# STM32F070F6P6 register map
File version: 1.0
Registers are 32-bit, access not given, reset 0x0 unless marked. A register's access mark holds for its fields unless they carry their own. Offsets are from the block's base; [hi:lo] are bit positions; {n}, {i} and the like mark numbered series.

## USART2
Base 0x40004400
Same registers: USART1 0x40013800
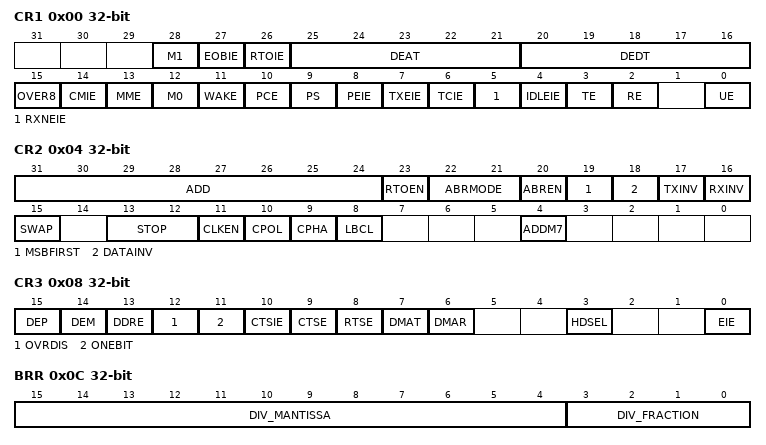
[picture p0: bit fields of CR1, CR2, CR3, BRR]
0x00 CR1
  [28] M1, [27] EOBIE, [26] RTOIE, [25:21] DEAT, [20:16] DEDT, [15] OVER8, [14] CMIE, [13] MME, [12] M0, [11] WAKE, [10] PCE, [9] PS, [8] PEIE, [7] TXEIE, [6] TCIE, [5] RXNEIE, [4] IDLEIE, [3] TE, [2] RE, [0] UE
0x04 CR2
  [31:24] ADD, [23] RTOEN, [22:21] ABRMODE, [20] ABREN, [19] MSBFIRST, [18] DATAINV, [17] TXINV, [16] RXINV, [15] SWAP, [13:12] STOP, [11] CLKEN, [10] CPOL, [9] CPHA, [8] LBCL, [4] ADDM7
0x08 CR3
  [15] DEP, [14] DEM, [13] DDRE, [12] OVRDIS, [11] ONEBIT, [10] CTSIE, [9] CTSE, [8] RTSE, [7] DMAT, [6] DMAR, [3] HDSEL, [0] EIE
0x0C BRR
  [15:4] DIV_MANTISSA, [3:0] DIV_FRACTION
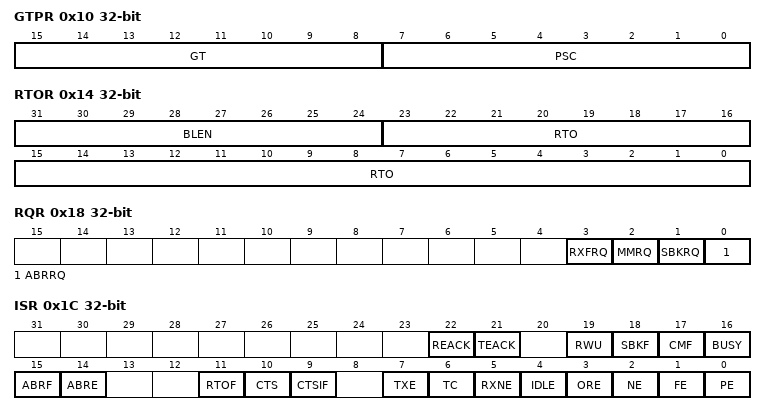
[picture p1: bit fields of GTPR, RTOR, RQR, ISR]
0x10 GTPR
  [15:8] GT, [7:0] PSC
0x14 RTOR
  [31:24] BLEN, [23:0] RTO
0x18 RQR
  [3] RXFRQ, [2] MMRQ, [1] SBKRQ, [0] ABRRQ
0x1C ISR
  [22] REACK, [21] TEACK, [19] RWU, [18] SBKF, [17] CMF, [16] BUSY, [15] ABRF, [14] ABRE, [11] RTOF, [10] CTS, [9] CTSIF, [7] TXE, [6] TC, [5] RXNE, [4] IDLE, [3] ORE, [2] NE, [1] FE, [0] PE
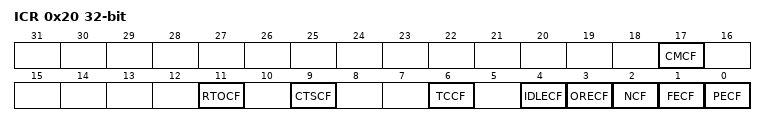
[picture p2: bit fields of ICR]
0x20 ICR
  [17] CMCF, [11] RTOCF, [9] CTSCF, [6] TCCF, [4] IDLECF, [3] ORECF, [2] NCF, [1] FECF, [0] PECF
0x24 RDR 16-bit
0x28 TDR 16-bit

## I2C1
Base 0x40005400
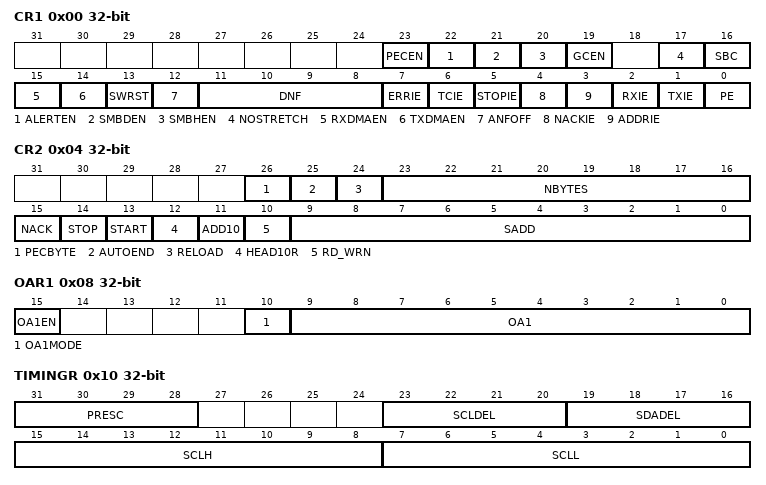
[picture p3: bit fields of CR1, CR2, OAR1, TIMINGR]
0x00 CR1
  [23] PECEN, [22] ALERTEN, [21] SMBDEN, [20] SMBHEN, [19] GCEN, [17] NOSTRETCH, [16] SBC, [15] RXDMAEN, [14] TXDMAEN, [13] SWRST, [12] ANFOFF, [11:8] DNF, [7] ERRIE, [6] TCIE, [5] STOPIE, [4] NACKIE, [3] ADDRIE, [2] RXIE, [1] TXIE, [0] PE
0x04 CR2
  [26] PECBYTE, [25] AUTOEND, [24] RELOAD, [23:16] NBYTES, [15] NACK, [14] STOP, [13] START, [12] HEAD10R, [11] ADD10, [10] RD_WRN, [9:0] SADD
0x08 OAR1
  [15] OA1EN, [10] OA1MODE, [9:0] OA1
0x0C OAR2
  [15] OA2EN, [10] OA2MASK04, [10:9] OA2MASK06, [10:8] OA2MSK, [7:1] OA2
0x10 TIMINGR
  [31:28] PRESC, [23:20] SCLDEL, [19:16] SDADEL, [15:8] SCLH, [7:0] SCLL
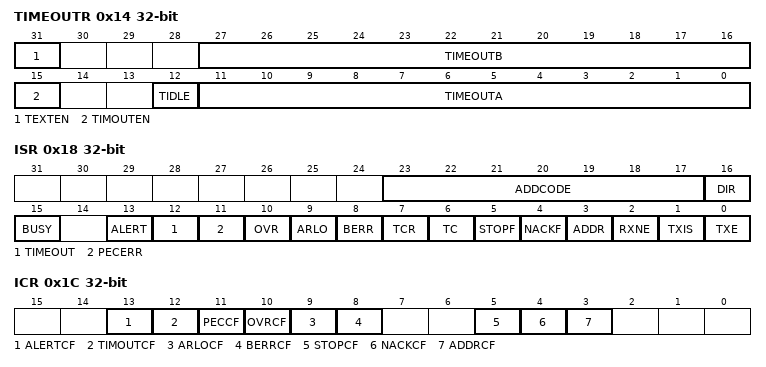
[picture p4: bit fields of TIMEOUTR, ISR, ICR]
0x14 TIMEOUTR
  [31] TEXTEN, [27:16] TIMEOUTB, [15] TIMOUTEN, [12] TIDLE, [11:0] TIMEOUTA
0x18 ISR
  [23:17] ADDCODE, [16] DIR, [15] BUSY, [13] ALERT, [12] TIMEOUT, [11] PECERR, [10] OVR, [9] ARLO, [8] BERR, [7] TCR, [6] TC, [5] STOPF, [4] NACKF, [3] ADDR, [2] RXNE, [1] TXIS, [0] TXE
0x1C ICR
  [13] ALERTCF, [12] TIMOUTCF, [11] PECCF, [10] OVRCF, [9] ARLOCF, [8] BERRCF, [5] STOPCF, [4] NACKCF, [3] ADDRCF
0x20 PECR
  [7:0] PEC
0x24 RXDR
  [7:0] RXDATA
0x28 TXDR
  [7:0] TXDATA

## USB
Base 0x40005C00
{0x0+4i} EP{i}R 16-bit (i=0..7)
0x40 CNTR 16-bit
0x44 ISTR 16-bit
0x48 FNR 16-bit
0x4C DADDR 16-bit
0x50 BTABLE 16-bit
0x54 LPMCSR 16-bit
0x58 BCDR 16-bit

## PWR
Base 0x40007000
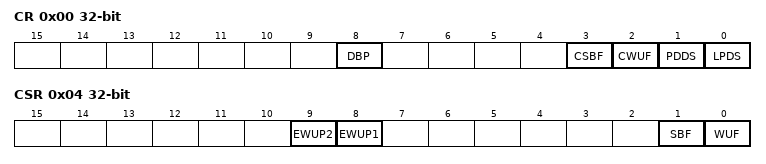
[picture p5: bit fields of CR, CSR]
0x00 CR
  [8] DBP, [3] CSBF, [2] CWUF, [1] PDDS, [0] LPDS
0x04 CSR
  [9] EWUP2, [8] EWUP1, [1] SBF, [0] WUF

## SYSCFG
Base 0x40010000
0x00 CFGR1
  [23] I2C_FMP_PA10, [22] I2C_FMP_PA9, [20] I2C_FMP_I2C1, [n+10] I2C_FMP_PB{n} (n=6..9), [12] TIM17_DMA_RMP, [11] TIM16_DMA_RMP, [10] USART1RX_DMA_RMP, [9] USART1TX_DMA_RMP, [12:8] DMA_RMP, [4] PA11_PA12_RMP, [1:0] MEM_MODE
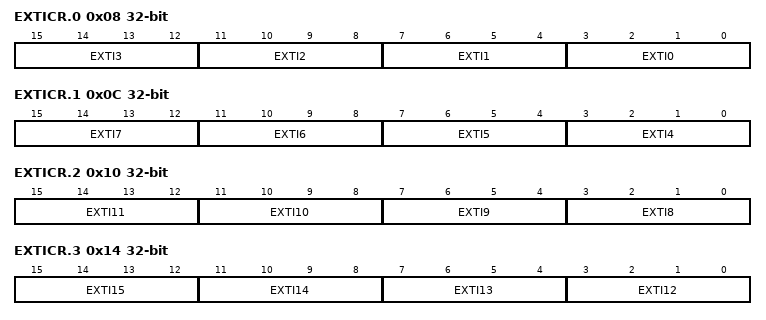
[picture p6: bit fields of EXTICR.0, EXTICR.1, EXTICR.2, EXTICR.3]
0x08 EXTICR.0
  [4n+3:4n] EXTI{n} (n=0..3)
0x0C EXTICR.1
  [4n-13:4n-16] EXTI{n} (n=4..7)
0x10 EXTICR.2
  [4n-29:4n-32] EXTI{n} (n=8..11)
0x14 EXTICR.3
  [4n-45:4n-48] EXTI{n} (n=12..15)
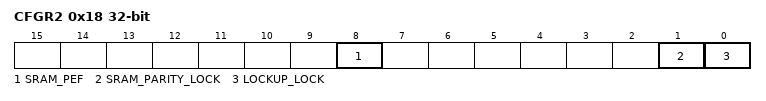
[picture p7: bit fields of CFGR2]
0x18 CFGR2
  [8] SRAM_PEF, [1] SRAM_PARITY_LOCK, [0] LOCKUP_LOCK

## EXTI
Base 0x40010400
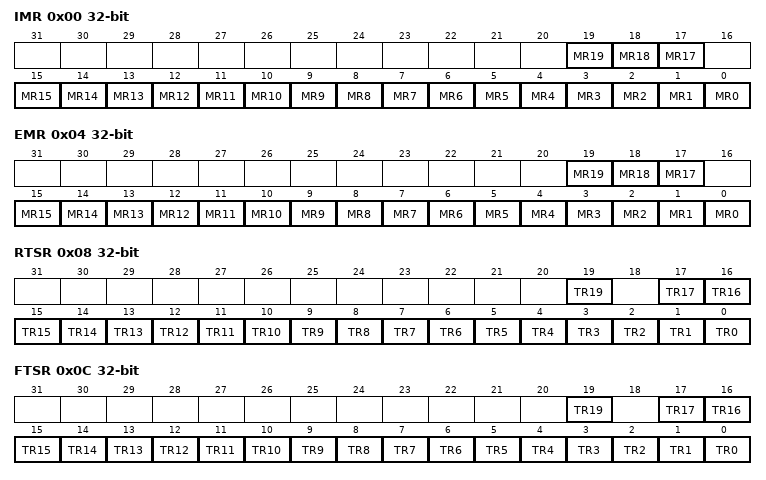
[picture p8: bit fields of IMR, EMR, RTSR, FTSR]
0x00 IMR
  [19] MR19, [18] MR18, [17] MR17, [n] MR{n} (n=0..15)
0x04 EMR
  [19] MR19, [18] MR18, [17] MR17, [n] MR{n} (n=0..15)
0x08 RTSR
  [19] TR19, [n] TR{n} (n=0..17)
0x0C FTSR
  [19] TR19, [n] TR{n} (n=0..17)
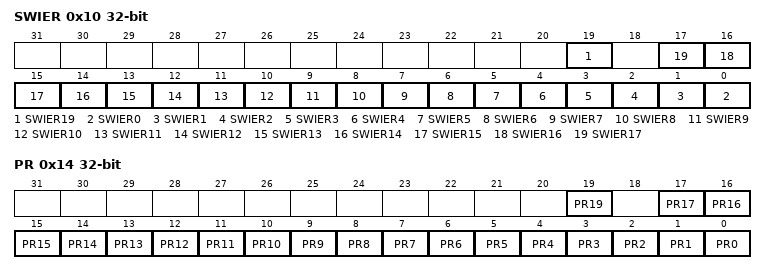
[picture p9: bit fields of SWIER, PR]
0x10 SWIER
  [19] SWIER19, [n] SWIER{n} (n=0..17)
0x14 PR
  [19] PR19, [n] PR{n} (n=0..17)

## ADC1
Base 0x40012400
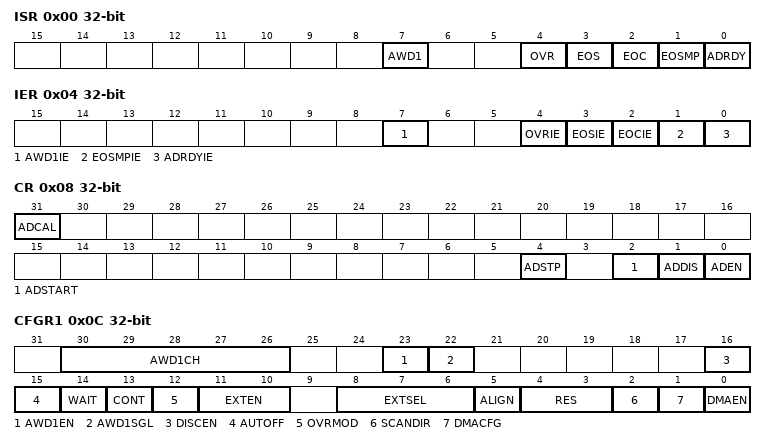
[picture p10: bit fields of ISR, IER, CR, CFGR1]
0x00 ISR
  [7] AWD1, [4] OVR, [3] EOS, [2] EOC, [1] EOSMP, [0] ADRDY
0x04 IER
  [7] AWD1IE, [4] OVRIE, [3] EOSIE, [2] EOCIE, [1] EOSMPIE, [0] ADRDYIE
0x08 CR
  [31] ADCAL, [4] ADSTP, [2] ADSTART, [1] ADDIS, [0] ADEN
0x0C CFGR1
  [30:26] AWD1CH, [23] AWD1EN, [22] AWD1SGL, [16] DISCEN, [15] AUTOFF, [14] WAIT, [13] CONT, [12] OVRMOD, [11:10] EXTEN, [8:6] EXTSEL, [5] ALIGN, [4:3] RES, [2] SCANDIR, [1] DMACFG, [0] DMAEN
0x10 CFGR2
  [31:30] CKMODE
0x14 SMPR
  [2:0] SMP
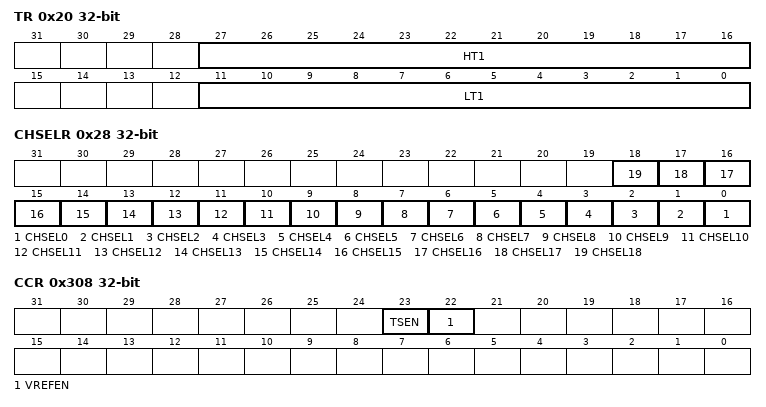
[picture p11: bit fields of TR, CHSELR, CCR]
0x20 TR
  [27:16] HT1, [11:0] LT1
0x28 CHSELR
  [n] CHSEL{n} (n=0..18)
0x40 DR
  [15:0] DATA
0x308 CCR
  [23] TSEN, [22] VREFEN
